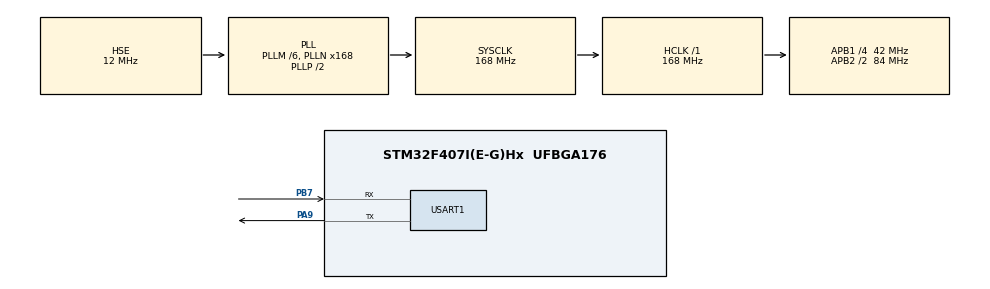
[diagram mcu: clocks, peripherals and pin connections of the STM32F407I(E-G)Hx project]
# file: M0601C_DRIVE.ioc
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Dma.Request0=USART1_RX
Dma.Request1=USART1_TX
Dma.USART1_RX.0.Direction=DMA_PERIPH_TO_MEMORY
Dma.USART1_RX.0.FIFOMode=DMA_FIFOMODE_DISABLE
Dma.USART1_RX.0.Instance=DMA2_Stream2
Dma.USART1_RX.0.MemDataAlignment=DMA_MDATAALIGN_BYTE
Dma.USART1_RX.0.MemInc=DMA_MINC_ENABLE
Dma.USART1_RX.0.Mode=DMA_NORMAL
Dma.USART1_RX.0.PeriphDataAlignment=DMA_PDATAALIGN_BYTE
Dma.USART1_RX.0.PeriphInc=DMA_PINC_DISABLE
Dma.USART1_RX.0.Priority=DMA_PRIORITY_LOW
Dma.USART1_TX.1.Direction=DMA_MEMORY_TO_PERIPH
Dma.USART1_TX.1.FIFOMode=DMA_FIFOMODE_DISABLE
Dma.USART1_TX.1.Instance=DMA2_Stream7
Dma.USART1_TX.1.MemDataAlignment=DMA_MDATAALIGN_BYTE
Dma.USART1_TX.1.MemInc=DMA_MINC_ENABLE
Dma.USART1_TX.1.Mode=DMA_NORMAL
Dma.USART1_TX.1.PeriphDataAlignment=DMA_PDATAALIGN_BYTE
Dma.USART1_TX.1.PeriphInc=DMA_PINC_DISABLE
Dma.USART1_TX.1.Priority=DMA_PRIORITY_LOW
Mcu.Family=STM32F4
Mcu.Name=STM32F407I(E-G)Hx
Mcu.Package=UFBGA176
NVIC.DMA2_Stream2_IRQn=true\:0\:0\:false\:false\:true\:false\:true\:true
NVIC.DMA2_Stream7_IRQn=true\:0\:0\:false\:false\:true\:false\:true\:true
NVIC.PriorityGroup=NVIC_PRIORITYGROUP_4
NVIC.USART1_IRQn=true\:0\:0\:false\:false\:true\:true\:true\:true
PA13.Mode=Serial_Wire
PA13.Signal=SYS_JTMS-SWDIO
PA14.Mode=Serial_Wire
PA14.Signal=SYS_JTCK-SWCLK
PA9.Mode=Asynchronous
PA9.Signal=USART1_TX
PB7.Mode=Asynchronous
PB7.Signal=USART1_RX
PH0-OSC_IN.Mode=HSE-External-Oscillator
PH0-OSC_IN.Signal=RCC_OSC_IN
PH1-OSC_OUT.Mode=HSE-External-Oscillator
PH1-OSC_OUT.Signal=RCC_OSC_OUT
ProjectManager.HeapSize=0x200
ProjectManager.StackSize=0x400
ProjectManager.TargetToolchain=MDK-ARM V5.32
RCC.48MHZClocksFreq_Value=84000000
RCC.AHBFreq_Value=168000000
RCC.APB1CLKDivider=RCC_HCLK_DIV4
RCC.APB1Freq_Value=42000000
RCC.APB1TimFreq_Value=84000000
RCC.APB2CLKDivider=RCC_HCLK_DIV2
RCC.APB2Freq_Value=84000000
RCC.APB2TimFreq_Value=168000000
RCC.CortexFreq_Value=168000000
RCC.HCLKFreq_Value=168000000
RCC.HSE_VALUE=12000000
RCC.HSI_VALUE=16000000
RCC.LSE_VALUE=32768
RCC.PLLM=6
RCC.PLLN=168
RCC.PLLSourceVirtual=RCC_PLLSOURCE_HSE
RCC.SYSCLKFreq_VALUE=168000000
RCC.SYSCLKSource=RCC_SYSCLKSOURCE_PLLCLK
RCC.VCOOutputFreq_Value=336000000
USART1.VirtualMode=VM_ASYNC
board=custom

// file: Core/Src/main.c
/* USER CODE BEGIN Header */
/**
 ******************************************************************************
 * @file           : main.c
 * @brief          : Main program body
 ******************************************************************************
 * @attention
 *
 * Copyright (c) 2026 STMicroelectronics.
 * All rights reserved.
 *
 * This software is licensed under terms that can be found in the LICENSE file
 * in the root directory of this software component.
 * If no LICENSE file comes with this software, it is provided AS-IS.
 *
 ******************************************************************************
 */
/* USER CODE END Header */
#include "main.h"
#include "dma.h"
#include "usart.h"
#include "gpio.h"

/* USER CODE BEGIN Includes */
#include "motor_driver.h" /* M0601C 电机驱动模块头文件 */
#include <string.h>
#include <stdio.h>
/* USER CODE END Includes */

/* USER CODE BEGIN PV */
/* 全局变量：电机反馈数据（调试器可查看） */
MotorFeedback_t g_motorFeedback = {0};
MotorStatus_t g_motorStatus = {0};  /* 解析后的电机状态 */
uint8_t g_feedbackCount = 0; /* 收到的反馈帧计数 */

/* 全局调试信息实例 */
DebugInfo_t g_debug = {0};

/* 为了兼容性保留旧变量 */
uint8_t g_dmaRxStarted = 0;
uint8_t g_rxCpltCallback = 0;
uint8_t g_crcError = 0;
uint8_t g_rxBufRaw[10] = {0};
/* USER CODE END PV */

void SystemClock_Config(void);
/* USER CODE BEGIN PFP */
/* 声明电机驱动函数 */
extern HAL_StatusTypeDef MOTOR_SendFeedbackCmd(uint8_t motorId);
/* USER CODE END PFP */

int main(void)
{

  /* MCU Configuration--------------------------------------------------------*/

  /* Reset of all peripherals, Initializes the Flash interface and the Systick. */
  HAL_Init();

  /* Configure the system clock */
  SystemClock_Config();

  /* Initialize all configured peripherals */
  MX_GPIO_Init();
  MX_DMA_Init();
  MX_USART1_UART_Init();
  /* USER CODE BEGIN 2 */

  /*
   * M0601C 电机持续运行程序
   * 电机ID: 1
   * 目标: 以最高转速 330 RPM 持续运行，并通过调试器查看反馈数据
   */

  /* 上电延时等待电机初始化 */
  HAL_Delay(2000);

  /* LED闪烁2次，指示程序启动 */
  for (int i = 0; i < 2; i++)
  {
    HAL_GPIO_WritePin(GPIOH, GPIO_PIN_10, GPIO_PIN_SET);
    HAL_Delay(200);
    HAL_GPIO_WritePin(GPIOH, GPIO_PIN_10, GPIO_PIN_RESET);
    HAL_Delay(200);
  }

  /* 启动 DMA 接收 */
  HAL_StatusTypeDef status = MOTOR_StartReceive();
  g_dmaRxStarted = (status == HAL_OK) ? 1 : 0;
  g_debug.dmaRxStarted = g_dmaRxStarted;

  /* 以 10 RPM 正转运行 */
  MOTOR_SetSpeed(1, 10);

  /* LED常亮指示电机运行中 */
  HAL_GPIO_WritePin(GPIOH, GPIO_PIN_11, GPIO_PIN_SET);

  /* USER CODE END 2 */

  /* Infinite loop */
  while (1)
  {

    /* USER CODE BEGIN 3 */
    /* 重新启动 DMA 接收（确保每次都能捕获新数据） */
    MOTOR_StartReceive();

    /* 发送反馈请求 */
    HAL_StatusTypeDef txStatus = MOTOR_SendFeedbackCmd(1);
    g_debug.txStatus = (txStatus == HAL_OK) ? 1 : 0;

    /* 等待电机返回数据 */
    HAL_Delay(100);

    /* 获取反馈数据 */
    MotorFeedback_t *pFeedback = MOTOR_GetFeedback();
    if (pFeedback->isValid)
    {
      /* 复制到全局变量供调试器查看 */
      memcpy(&g_motorFeedback, pFeedback, sizeof(MotorFeedback_t));

      /* 解析原始数据成物理量 */
      MOTOR_ParseFeedback(pFeedback, &g_motorStatus);

      g_feedbackCount++;

      /* 同步更新调试结构体 */
      g_debug.rxBufValid = 1;

      /* LED闪烁指示收到反馈 */
      HAL_GPIO_TogglePin(GPIOH, GPIO_PIN_10);
    }

    /* 更新调试结构体的计数器 */
    g_debug.rxCpltCallback = g_rxCpltCallback;
    g_debug.crcError = g_crcError;

    HAL_Delay(400);  /* 总共500ms */
  }
  /* USER CODE END 3 */
}

void SystemClock_Config(void)
{
  RCC_OscInitTypeDef RCC_OscInitStruct = {0};
  RCC_ClkInitTypeDef RCC_ClkInitStruct = {0};

  /** Configure the main internal regulator output voltage
   */
  __HAL_RCC_PWR_CLK_ENABLE();
  __HAL_PWR_VOLTAGESCALING_CONFIG(PWR_REGULATOR_VOLTAGE_SCALE1);

  /** Initializes the RCC Oscillators according to the specified parameters
   * in the RCC_OscInitTypeDef structure.
   */
  RCC_OscInitStruct.OscillatorType = RCC_OSCILLATORTYPE_HSE;
  RCC_OscInitStruct.HSEState = RCC_HSE_ON;
  RCC_OscInitStruct.PLL.PLLState = RCC_PLL_ON;
  RCC_OscInitStruct.PLL.PLLSource = RCC_PLLSOURCE_HSE;
  RCC_OscInitStruct.PLL.PLLM = 6;
  RCC_OscInitStruct.PLL.PLLN = 168;
  RCC_OscInitStruct.PLL.PLLP = RCC_PLLP_DIV2;
  RCC_OscInitStruct.PLL.PLLQ = 4;
  if (HAL_RCC_OscConfig(&RCC_OscInitStruct) != HAL_OK)
  {
    Error_Handler();
  }

  /** Initializes the CPU, AHB and APB buses clocks
   */
  RCC_ClkInitStruct.ClockType = RCC_CLOCKTYPE_HCLK | RCC_CLOCKTYPE_SYSCLK | RCC_CLOCKTYPE_PCLK1 | RCC_CLOCKTYPE_PCLK2;
  RCC_ClkInitStruct.SYSCLKSource = RCC_SYSCLKSOURCE_PLLCLK;
  RCC_ClkInitStruct.AHBCLKDivider = RCC_SYSCLK_DIV1;
  RCC_ClkInitStruct.APB1CLKDivider = RCC_HCLK_DIV4;
  RCC_ClkInitStruct.APB2CLKDivider = RCC_HCLK_DIV2;

  if (HAL_RCC_ClockConfig(&RCC_ClkInitStruct, FLASH_LATENCY_5) != HAL_OK)
  {
    Error_Handler();
  }
}

void Error_Handler(void)
{
  __disable_irq();
  while (1)
  {
  }
}
